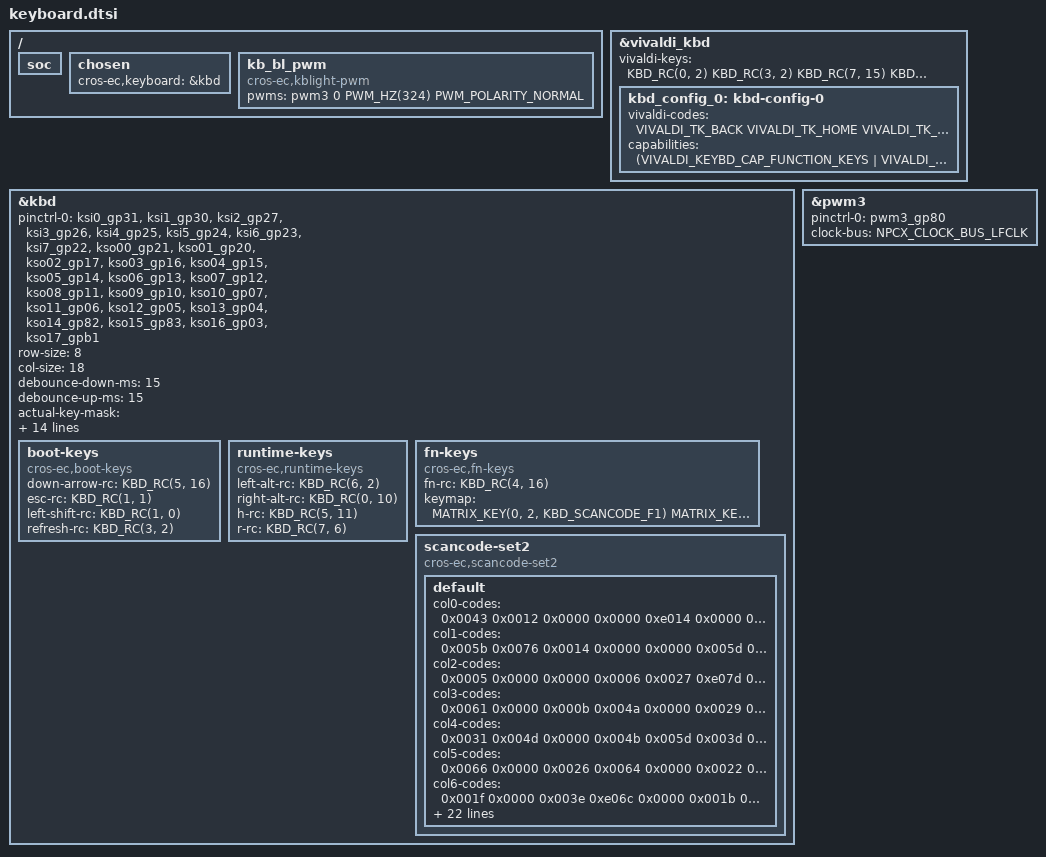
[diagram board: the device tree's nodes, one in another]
/* Copyright 2026 The ChromiumOS Authors
 * Use of this source code is governed by a BSD-style license that can be
 * found in the LICENSE file.
 */

#include <zephyr/dt-bindings/input/keymap.h>

/ {
	soc {
		/* delete this because zmake complains that cros_kb_raw and kbd
		 * has same address */
		/delete-node/ cros-kb-raw@400a3000;
	};

	chosen {
		cros-ec,keyboard = &kbd;
	};

	kb_bl_pwm {
		compatible = "cros-ec,kblight-pwm";
		pwms = <&pwm3 0 PWM_HZ(324) PWM_POLARITY_NORMAL>;
		status = "okay";
	};
};

&vivaldi_kbd {
	vivaldi-keys = <
		KBD_RC(0, 2)    /* T1 */
		KBD_RC(3, 2)    /* T2 */
		KBD_RC(7, 15)   /* T3 */
		KBD_RC(1, 13)   /* T4 */
		KBD_RC(0, 9)    /* T5 */
		KBD_RC(2, 3)    /* T6 */
		KBD_RC(0, 7)    /* T7 */
		KBD_RC(3, 12)   /* T8 */
		KBD_RC(0, 8)    /* T9 */
		KBD_RC(4, 15)   /* T10 */
		KBD_RC(0, 11)   /* T11 */
		KBD_RC(0, 12)   /* T12 */
		KBD_RC(6, 7)    /* T13 */
		KBD_RC(6, 1)    /* T14 */
	>;

	kbd_config_0: kbd-config-0{
		vivaldi-codes = <
			VIVALDI_TK_BACK               /* T1 */
			VIVALDI_TK_HOME               /* T2 */
			VIVALDI_TK_OVERVIEW           /* T3 */
			VIVALDI_TK_FULLSCREEN         /* T4 */
			VIVALDI_TK_SNAPSHOT           /* T5 */
			VIVALDI_TK_BRIGHTNESS_DOWN    /* T6 */
			VIVALDI_TK_BRIGHTNESS_UP      /* T7 */
			VIVALDI_TK_KBD_BKLIGHT_TOGGLE /* T8 */
			VIVALDI_TK_MICMUTE            /* T9 */
			VIVALDI_TK_VOL_MUTE           /* T10 */
			VIVALDI_TK_VOL_DOWN           /* T11 */
			VIVALDI_TK_VOL_UP             /* T12 */
			VIVALDI_TK_ACCESSIBILITY      /* T13 */
			VIVALDI_TK_DICTATE            /* T14 */
		>;
		capabilities = < (VIVALDI_KEYBD_CAP_FUNCTION_KEYS |
				VIVALDI_KEYBD_CAP_SCRNLOCK_KEY |
				VIVALDI_KEYBD_CAP_ASSISTANT_KEY) >;
	};
};

&kbd {
	status = "okay";
	pinctrl-0 = <
		&ksi0_gp31
		&ksi1_gp30
		&ksi2_gp27
		&ksi3_gp26
		&ksi4_gp25
		&ksi5_gp24
		&ksi6_gp23
		&ksi7_gp22
		&kso00_gp21
		&kso01_gp20
		&kso02_gp17
		&kso03_gp16
		&kso04_gp15
		&kso05_gp14
		&kso06_gp13
		&kso07_gp12
		&kso08_gp11
		&kso09_gp10
		&kso10_gp07
		&kso11_gp06
		&kso12_gp05
		&kso13_gp04
		&kso14_gp82
		&kso15_gp83
		&kso16_gp03
		&kso17_gpb1
	>;
	row-size = <8>;
	col-size = <18>;
	debounce-down-ms = <15>;
	debounce-up-ms = <15>;
	actual-key-mask = <
		0x53  /* C0  rows 0/1/4/6 */
		0x6f  /* C1  rows 0/1/2/3/5/6 */
		0x7d  /* C2  rows 0/2/3/4/5/6 */
		0x2d  /* C3  rows 0/2/3/5 */
		0xff  /* C4  rows 0-7 */
		0xef  /* C5  rows 0/1/2/3/5/6/7 */
		0xaf  /* C6  rows 0/1/2/3/5/7 */
		0xfd  /* C7  rows 0/2/3/4/5/6/7 */
		0xef  /* C8  rows 0/1/2/3/5/6/7 */
		0xdd  /* C9  rows 0/2/3/4/6/7 */
		0xe5  /* C10 rows 0/2/5/6/7 */
		0xfd  /* C11 rows 0/2/3/4/5/6/7 */
		0xef  /* C12 rows 0/1/2/3/5/6/7 */
		0xef  /* C13 rows 0/1/2/3/5/6/7 */
		0xcf  /* C14 rows 0/1/2/3/6/7 */
		0xb9  /* C15 rows 0/3/4/5/7 */
		0xfd  /* C16 rows 0/2/3/4/5/6/7 */
		0xc2  /* C17 rows 1/6/7 */
	>;

	pinctrl-1 = <
		&ksi0_gpio_gp31
		&ksi1_gpio_gp30
		&ksi2_gpio_gp27
		&ksi3_gpio_gp26
		&ksi4_gpio_gp25
		&ksi5_gpio_gp24
		&ksi6_gpio_gp23
		&ksi7_gpio_gp22
		&kso00_gpio_gp21
		&kso01_gpio_gp20
		&kso02_gpio_gp17
		&kso03_gpio_gp16
		&kso04_gpio_gp15
		&kso05_gpio_gp14
		&kso06_gpio_gp13
		&kso07_gpio_gp12
		&kso08_gpio_gp11
		&kso09_gpio_gp10
		&kso10_gpio_gp07
		&kso11_gpio_gp06
		&kso12_gpio_gp05
		&kso13_gpio_gp04
		&kso14_gpio_gp82
		&kso15_gpio_gp83
		&kso16_gpio_gp03
		&kso17_gpio_gpb1
	>;
	pinctrl-names = "default", "sleep";

	boot-keys {
		compatible = "cros-ec,boot-keys";
		down-arrow-rc = <KBD_RC(5, 16)>;
		esc-rc = <KBD_RC(1, 1)>;
		left-shift-rc = <KBD_RC(1, 0)>;
		refresh-rc = <KBD_RC(3, 2)>;
	};

	runtime-keys {
		compatible = "cros-ec,runtime-keys";
		left-alt-rc = <KBD_RC(6, 2)>;
		right-alt-rc = <KBD_RC(0, 10)>;
		h-rc = <KBD_RC(5, 11)>;
		r-rc = <KBD_RC(7, 6)>;
	};

	fn-keys {
		compatible = "cros-ec,fn-keys";

		fn-rc = <KBD_RC(4, 16)>;
		keymap = <
			MATRIX_KEY(0, 2, KBD_SCANCODE_F1)
			MATRIX_KEY(3, 2, KBD_SCANCODE_F2)
			MATRIX_KEY(7, 15, KBD_SCANCODE_F3)
			MATRIX_KEY(1, 13, KBD_SCANCODE_F4)
			MATRIX_KEY(0, 9, KBD_SCANCODE_F5)
			MATRIX_KEY(2, 3, KBD_SCANCODE_F6)
			MATRIX_KEY(0, 7, KBD_SCANCODE_F7)
			MATRIX_KEY(3, 12, KBD_SCANCODE_F8)
			MATRIX_KEY(0, 8, KBD_SCANCODE_F9)
			MATRIX_KEY(4, 15, KBD_SCANCODE_F10)
			MATRIX_KEY(0, 11, KBD_SCANCODE_F11)
			MATRIX_KEY(0, 12, KBD_SCANCODE_F12)
			MATRIX_KEY(6, 7, KBD_SCANCODE_F13)
			MATRIX_KEY(6, 1, KBD_SCANCODE_F14)

			MATRIX_KEY(4, 2, KBD_SCANCODE_CAPSLOCK)
			MATRIX_KEY(0, 5, KBD_SCANCODE_DELETE)
			MATRIX_KEY(2, 11, KBD_SCANCODE_PAGEUP)
			MATRIX_KEY(5, 16, KBD_SCANCODE_PAGEDOWN)
			MATRIX_KEY(0, 15, KBD_SCANCODE_HOME)
			MATRIX_KEY(1, 17, KBD_SCANCODE_END)
		>;
	};

	scancode-set2 {
		compatible = "cros-ec,scancode-set2";

		/*
		 * Key positions follow the new keyboard matrix (Horus 2.1).
		 * Scancodes are carried over from the old matrix by key ID, so a
		 * key that only changed position keeps its original code.
		 *
		 * TODO: the following 16 cells belong to keys that are new in this
		 * matrix and have no scancode assigned yet. They are set to 0x0000
		 * so that pressing them reports nothing:
		 *   (1,5) (1,6) (1,8) (1,14) (2,2) (2,4) (2,7) (2,13)
		 *   (3,1) (3,11) (3,13) (5,12) (6,5) (6,14) (6,16) (7,12)
		 */
		default {
			col0-codes  = <0x0043 0x0012 0x0000 0x0000 0xe014 0x0000 0x0067 0x0000>;
			col1-codes  = <0x005b 0x0076 0x0014 0x0000 0x0000 0x005d 0x0017 0x0000>;
			col2-codes  = <0x0005 0x0000 0x0000 0x0006 0x0027 0xe07d 0x0011 0x0000>;
			col3-codes  = <0x0061 0x0000 0x000b 0x004a 0x0000 0x0029 0x0000 0x0000>;
			col4-codes  = <0x0031 0x004d 0x0000 0x004b 0x005d 0x003d 0x0025 0x001d>;
			col5-codes  = <0x0066 0x0000 0x0026 0x0064 0x0000 0x0022 0x0000 0x0036>;
			col6-codes  = <0x001f 0x0000 0x003e 0xe06c 0x0000 0x001b 0x0000 0x002d>;
			col7-codes  = <0x0083 0x0000 0x0000 0x002c 0x001c 0x003c 0x000f 0x0049>;
			col8-codes  = <0x0001 0x0000 0x0034 0x004e 0x0000 0x0024 0x006a 0x0045>;
			col9-codes  = <0x0003 0x0000 0x001e 0x002f 0x003b 0x0000 0x0041 0x001a>;
			col10-codes = <0xe011 0x0000 0x0046 0x0000 0x0000 0x002b 0x004c 0x002a>;
			col11-codes = <0x0078 0x0000 0xe075 0x0000 0xe071 0x0033 0x000e 0x0055>;
			col12-codes = <0x0007 0x0044 0xe069 0x000a 0x0000 0x0000 0x0015 0x0000>;
			col13-codes = <0x0035 0x000c 0x0000 0x0000 0x0000 0x003a 0x0052 0x0021>;
			col14-codes = <0x0023 0x0000 0x0032 0x0016 0x0000 0x0000 0x0000 0x0051>;
			col15-codes = <0xe06b 0x0000 0x0000 0xe01f 0x0009 0x000d 0x0000 0x0004>;
			col16-codes = <0xe07a 0x0000 0x0054 0x002e 0x0037 0xe072 0x0000 0x0042>;
			col17-codes = <0x0000 0xe074 0x0000 0x0000 0x0000 0x0000 0x0059 0x005a>;
		};
	};
};

&pwm3 {
	status = "okay";
	pinctrl-0 = <&pwm3_gp80>;
	pinctrl-names = "default";
	clock-bus = "NPCX_CLOCK_BUS_LFCLK";
};
